# DISPC_GFX1 register map
Vendor: Texas Instruments
Peripheral module from a debugger description file (folder DM50x).
Registers are 32-bit, access per field, reset 0x0 unless marked. A register's access mark holds for its fields unless they carry their own. Offsets are as the file gives them; lines under a group give offsets from that group; [hi:lo] are bit positions; {n}, {i} and the like mark numbered series; 'fields as' and 'values as' point back to an identical list; <NAME> marks a mode.

## DISPC_GFX1
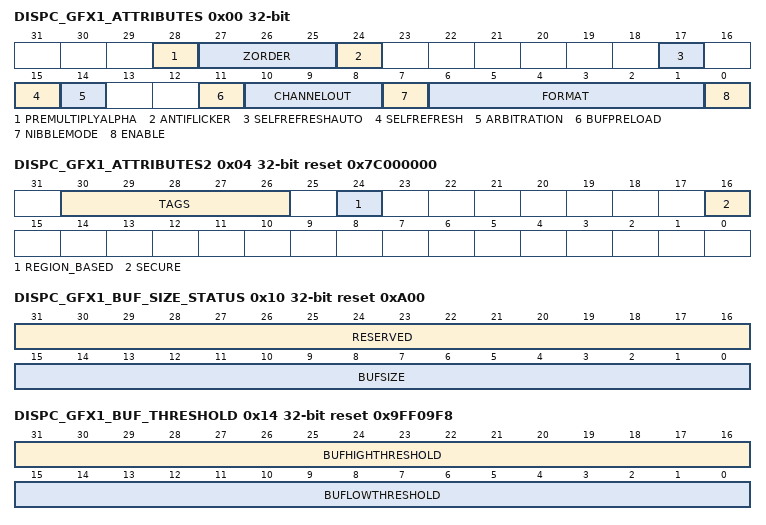
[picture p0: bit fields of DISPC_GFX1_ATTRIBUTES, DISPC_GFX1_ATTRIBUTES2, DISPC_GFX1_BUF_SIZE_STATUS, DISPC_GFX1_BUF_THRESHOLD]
0x00 DISPC_GFX1_ATTRIBUTES — The register configures the graphics attributes. Shadow register.
  [28] PREMULTIPLYALPHA rw — The field configures the DISPC GFX to process incoming data as premultiplied alpha data or non premultiplied alpha data. Default setting is non premultiplied alpha data.
    0=NONPREMULTIPLIEDALPHA (Non premultiplyalpha data color component); 1=PREMULTIPLIEDALPHA (Premultiplyalpha data color component)
  [27:25] ZORDER rw — Z-Order defining the priority of the layer compared to others when overlaying. It is SW responsibility to ensure that each layer connected to the same overlay manager has a different z-order value.
    1=Z-order 1: layer above layer with z-order value of 0 and below layers with z-order values of 2 and 3; 0=Z-order 0: layer above solid background color and below layer with higher Z-order values; 2=Z-order 2: layer above layers with z-order value of 0 and 1 and below layer with z-order value of 3; 4=Z-order 4: layer above layers with z-order value of 0, 1, 2 and 3 and below layer with z-order value of 5; 5=Z-order 5: layer above all the other layers except cursor; 3=Z-order 3: layer above layers with z-order value of 0, 1 and 2 and below layer with z-order value of 4
  [24] ANTIFLICKER rw — Anti-aliasing filtering using a 3-tap filter with hardcoded coefficients (1/4, 1/2, 1/4)
    0=AFDIS (Anti-aliasing disabled.); 1=AFENB (Anti-aliasing enabled.)
  [17] SELFREFRESHAUTO rw — Automatic self refresh mode
    0=SELFREFRESHAUTODIS (The transition from Selfrefresh 'disabled' to 'enabled' is controlled by SW); 1=SELFREFRESHAUTOEN (The transition from Selfrefresh 'disabled' to 'enabled' is controlled only by HW)
  [15] SELFREFRESH rw — Enables the self refresh of the graphics window from its own DMA buffer. This bit should be set only after havin set the GO bit of the channel and read back a zero in its field.
    0=SELFREFRESHDIS (The graphics pipeline accesses the interconnect to fetch data from the system memory.); 1=SELFREFRESHENB (The graphics pipeline does not need anymore to fetch data from memory. Only the graphics DMA buffer is used. It takes effect after the frame has been loaded in the DMA buffer.)
  [14] ARBITRATION rw — Determines the priority of the graphics pipeline. When the graphics pipeline is one of the high priority pipelines. The arbitration wheel gives always the priority first to the high priority pipelines using round-robin between them. When there is only normal priority pipelines sending requests, the round-robin applies between them.
    0=NORMALPRIO (The graphics pipeline is one of the normal priority pipeline.); 1=HIGHPRIO (The graphics pipeline is one of the high priority pipeline.)
  [11] BUFPRELOAD rw — Graphics Preload Value
    0=DEFVAL (H/W prefetches pixels up to the preload value defined in the preload register); 1=HIGHTHRES (H/W prefetches pixels up to high threshold value)
  [10:8] CHANNELOUT rw — Graphics Channel Out configuration wr: immediate
    0=VP1SEL (OVR1 (VP1)); 1=VP1SEL (OVR2); 4=WBSEL
  [7] NIBBLEMODE rw — Graphics Nibble mode (only for 1-, 2- and 4-bpp)
    0=NIBBLEMODEDIS (Nibble mode is disabled); 1=NIBBLEMODEEN (Nibble mode is enabled)
  [6:1] FORMAT rw — Graphics format. It defines the pixel format when fetching the graphics picture into memory.
    9=RGBA32_8888; 21=BITMAP8 (BITMAP8 (CLUT is required)); 8=ABGR32_8888; 5=ARGB16_1555; 46=XRGB32_2101010; 2=RGBA16_4444; 11=RGB24P_888 (RGB24-888 (24-bit container)); 4=BGR16_565; 1=ABGR16_4444; 40=XBGR32_8888; 0=ARGB16_4444; 37=XRGB16_1555; 32=XRGB16_4444 (xRGB12-4444); 3=RGB16_565; 48=XRGB64_16161616; 49=RGBX64_16161616; 17=RGBA64_16161616; 6=ABGR16_1555; 47=XBGR32_2101010; 10=BGRA32_8888; 38=XBGR16_1555; 16=ARGB64_16161616; 33=XBGR16_4444; 18=BITMAP1 (BITMAP1 (CLUT is required)); 19=BITMAP2 (BITMAP2 (CLUT is required)); 20=BITMAP4 (BITMAP4 (CLUT is required)); 14=ARGB32_2101010; 42=BGRX32_8888; 7=ARGB32_8888; 39=XRGB32_8888 (xRGB32-8888 (32-bit container)); 41=RGBX32_8888 (RGBx32-8888 (24-bit RGB aligned on MSB of the 32-bit container)); 15=ABGR32_2101010; 34=RGBX16_4444
  [0] ENABLE rw — Graphics Enable
    0=GRAPHICSDIS (Graphics disabled (graphics pipeline inactive and graphics window not present)); 1=GRAPHICSENB (Graphics enabled (graphics pipeline active and graphics window present on the screen))
0x04 DISPC_GFX1_ATTRIBUTES2 reset 0x7C000000 — The register configures the graphics attributes. Shadow register.
  [30:26] TAGS rw — Number of OCP TAGS to be used for the pipeline (from 1 to 32)
  [24] REGION_BASED rw — Enable region-based mechanism
    0=DISABLE; 1=ENABLE
  [16] SECURE rw — OCP requests corresponds to pipeline data are secure/unsecure. The bit-field can be modified only by secure transaction using MReqSecure qualifier.
0x08 DISPC_GFX1_BA_j_0 rw — The register configures the base address of the graphics buffer displayed in the graphics window (0 & 1 :for ping-pong mechanism with external trigger, based on the field polarity). Shadow register.
  [31:0] BA — Graphics base address When decompression is enabled bit[5:0] shall be set to 0. Base address of the graphics buffer (aligned on pixel size boundary) (in case of RGB24 packed format, 4-pixel alignment is required) When the TILER is addressed, the bits: [28:27] = 0x0 for 8-bit tiled [28:27] = 0x1 for 16-bit tiled [28:27] = 0x2 for 32-bit tiled [28:27] = 0x3 for page mode [31:29] = 0x0 for 0-degree view [31:29] = 0x1 for 180-degree view + mirroring [31:29] = 0x2 for 0-degree view + mirroring [31:29] = 0x3 for 180-degree view [31:29] = 0x4 for 270-degree view + mirroring [31:29] = 0x5 for 270-degree view [31:29] = 0x6 for 90-degree view [31:29] = 0x7 for 90-degree view + mirroring Otherwise the bits indicated the corresponding bit address to access the SDRAM.
0x0C DISPC_GFX1_BA_j_1 rw — The register configures the base address of the graphics buffer displayed in the graphics window (0 & 1 :for ping-pong mechanism with external trigger, based on the field polarity). Shadow register.
  fields as DISPC_GFX1_BA_j_0
0x10 DISPC_GFX1_BUF_SIZE_STATUS ro reset 0xA00 — The register defines the Graphics buffer size
  [31:16] RESERVED — Write 0's for future compatibility. Reads return 0
  [15:0] BUFSIZE — DMA buffer Size in number of 128-bits
0x14 DISPC_GFX1_BUF_THRESHOLD rw reset 0x9FF09F8 — The register configures the graphics buffer. Shadow register.
  [31:16] BUFHIGHTHRESHOLD — DMA buffer High Threshold Number of 128-bits defining the threshold value.
  [15:0] BUFLOWTHRESHOLD — DMA buffer Low Threshold Number of 128-bits defining the threshold value.
0x18 DISPC_GFX1_GLOBAL_ALPHA reset 0xFF — The register defines the global alpha value for the graphics pipeline. Shadow register.
  [7:0] GLOBALALPHA rw — Global alpha value from 0 to 255. 0 corresponds to fully transparent and 255 to fully opaque.
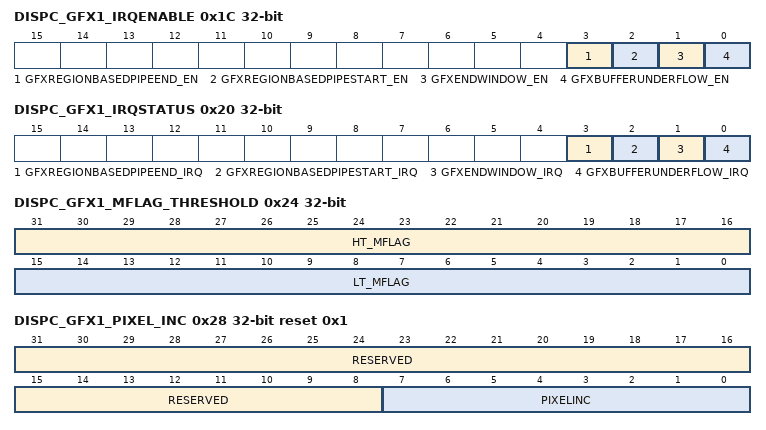
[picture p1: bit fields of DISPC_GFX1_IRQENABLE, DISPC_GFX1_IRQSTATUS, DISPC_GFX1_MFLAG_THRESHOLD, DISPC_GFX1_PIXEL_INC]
0x1C DISPC_GFX1_IRQENABLE — This register allows to mask/unmask the module internal sources of interrupt, on an event-by-event basis
  [3] GFXREGIONBASEDPIPEEND_EN rw — PIPE end window IRQ for region-based feature
    0=MASKED (GFXREGIONBASEDPIPEEND is masked); 1=GENINT (GFXREGIONBASEDPIPEEND generates an interrupt when it occurs)
  [2] GFXREGIONBASEDPIPESTART_EN rw — PIPE start window IRQ for region-based feature
    0=MASKED (GFXREGIONBASEDPIPESTART is masked); 1=GENINT (GFXREGIONBASEDPIPESTART generates an interrupt when it occurs)
  [1] GFXENDWINDOW_EN rw — The end of Gfx Window has been reached. It is detected by the overlay manager when the full graphics has been displayed.
    0=MASKED (GfxEndWindow is masked); 1=GENINT (GfxEndWindow generates an interrupt when it occurs)
  [0] GFXBUFFERUNDERFLOW_EN rw — Gfx DMA Buffer Underflow. The DMA buffer is not necessarly empty but required data are not present in the DMA buffer (due to out of order responses)
    0=MASKED (GfxBufferUnderflow is masked); 1=GENINT (GfxBufferUnderflow generates an interrupt when it occurs)
0x20 DISPC_GFX1_IRQSTATUS — This register regroups all the status of the module internal events that generate an interrupt. Write 1 to a given bit resets this bit
  [all] fields
    0=FALSE (READS: Event is false. WRITES: Status bit unchanged.); 1=TRUE (READS: Event is true (pending). WRITES: Status bit is reset.)
  [3] GFXREGIONBASEDPIPEEND_IRQ rw — PIPE end window IRQ for region-based feature
  [2] GFXREGIONBASEDPIPESTART_IRQ rw — PIPE start window IRQ for region-based feature
  [1] GFXENDWINDOW_IRQ rw — The end of Gfx Window has been reached. It is detected by the overlay manager when the full graphics has been displayed.
  [0] GFXBUFFERUNDERFLOW_IRQ rw — Gfx DMA Buffer Underflow. The DMA buffer is not necessarly empty but required data are not present in the DMA buffer (due to out of order responses)
0x24 DISPC_GFX1_MFLAG_THRESHOLD rw
  [31:16] HT_MFLAG, [15:0] LT_MFLAG
0x28 DISPC_GFX1_PIXEL_INC reset 0x1 — The register configures the number of bytes to increment between two pixels. Shadow register.
  [31:8] RESERVED ro — Write 0's for future compatibility. Reads return 0
  [7:0] PIXELINC rw — Number of bytes to increment between two pixels. Encoded unsigned value (from 1 to 255) to specify the number of bytes between two pixels in the graphics buffer. The value 0 is invalid. The value 1 means next pixel. The value 1+n*bpp means increment of n pixels.
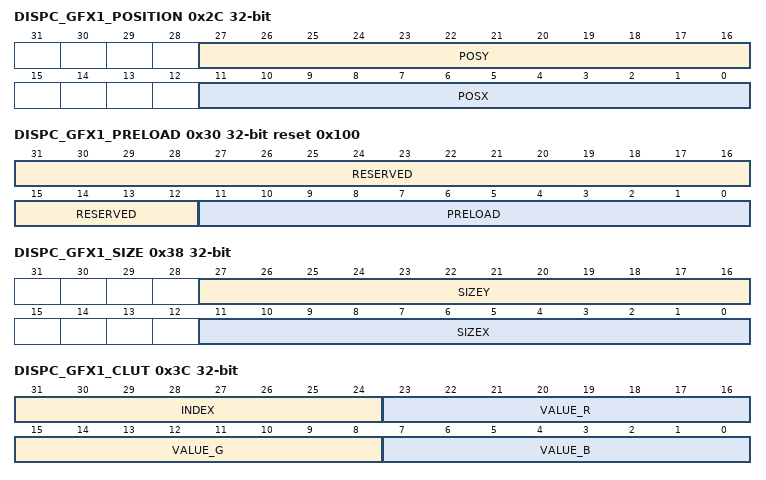
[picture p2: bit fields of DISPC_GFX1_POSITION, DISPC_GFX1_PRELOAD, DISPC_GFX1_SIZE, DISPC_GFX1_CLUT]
0x2C DISPC_GFX1_POSITION — The register configures the position of the graphics window. Shadow register.
  [27:16] POSY rw — Y position of the graphics window. Encoded value (from 0 to 4095) to specify the Y position of the graphics window on the screen. The line at the top has the Y-position 0.
  [11:0] POSX rw — X position of the graphics window. Encoded value (from 0 to 4095) to specify the X position of the graphics window on the screen. The first pixel on the left of the screen has the X-position 0.
0x30 DISPC_GFX1_PRELOAD reset 0x100 — The register configures the graphics DMA buffer Shadow register.
  [31:12] RESERVED ro — Write 0's for future compatibility. Reads return 0
  [11:0] PRELOAD rw — DMA buffer preload value Number of 128-bit words defining the preload value.
0x34 DISPC_GFX1_ROW_INC rw reset 0x1 — The register configures the number of bytes to increment at the end of the row. Shadow register.
  [31:0] ROWINC — Number of bytes to increment at the end of the row Encoded unsigned value to specify the number of bytes to increment at the end of the row in the graphics buffer. The value 0 is invalid. The value 1 means next pixel. The value 1+n*bpp means increment of n pixels. The value 1- (n+1)*bpp means decrement of n pixels.
0x38 DISPC_GFX1_SIZE — The register configures the size of the graphics window. Shadow register.
  [27:16] SIZEY rw — Number of lines of the graphics window. Encoded value (from 1 to 4096) to specify the number of lines of the graphics window (program size -1).
  [11:0] SIZEX rw — Number of pixels of the graphics window. Encoded value (from 1 to 4096) to specify the number of pixels per line of the graphics window (program size -1).
0x3C DISPC_GFX1_CLUT wo — The register configures the Color Look Up Table (CLUT) for GFX pipeline. CLUT is used in conjunction with bitmap formats
  [31:24] INDEX — Defines the location in the table where the bit-field VALUE is stored
  [23:16] VALUE_R — 8-bit value used to defined the value to store at the location in the table defined by the bit-field INDEX.
  [15:8] VALUE_G — 8-bit value used to defined the value to store at the location in the table defined by the bit-field INDEX.
  [7:0] VALUE_B — 8-bit value used to defined the value to store at the location in the table defined by the bit-field INDEX.
